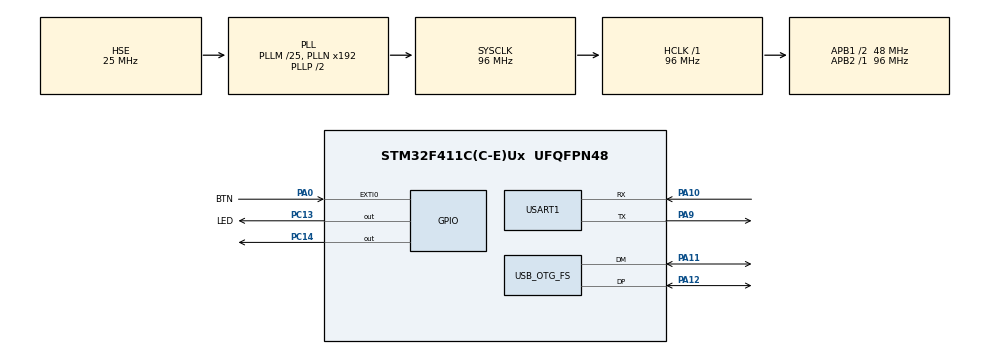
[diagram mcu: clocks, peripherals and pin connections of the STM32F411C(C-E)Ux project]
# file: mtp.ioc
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FREERTOS.Tasks01=mainTask,0,128,startMainTask,Default,NULL,Dynamic,NULL,NULL
FREERTOS.configUSE_NEWLIB_REENTRANT=1
Mcu.Family=STM32F4
Mcu.Name=STM32F411C(C-E)Ux
Mcu.Package=UFQFPN48
NVIC.OTG_FS_IRQn=true\:5\:0\:false\:false\:true\:true\:true\:true
NVIC.PriorityGroup=NVIC_PRIORITYGROUP_4
NVIC.TIM1_TRG_COM_TIM11_IRQn=true\:15\:0\:false\:false\:true\:false\:false\:true
NVIC.TimeBase=TIM1_TRG_COM_TIM11_IRQn
NVIC.TimeBaseIP=TIM11
PA0-WKUP.GPIO_Label=BTN
PA0-WKUP.GPIO_ModeDefaultEXTI=GPIO_MODE_IT_FALLING
PA0-WKUP.GPIO_PuPd=GPIO_PULLUP
PA0-WKUP.Signal=GPXTI0
PA10.Mode=Asynchronous
PA10.Signal=USART1_RX
PA11.Mode=Host_Only
PA11.Signal=USB_OTG_FS_DM
PA12.Mode=Host_Only
PA12.Signal=USB_OTG_FS_DP
PA13.Mode=Serial_Wire
PA13.Signal=SYS_JTMS-SWDIO
PA14.Mode=Serial_Wire
PA14.Signal=SYS_JTCK-SWCLK
PA9.Mode=Asynchronous
PA9.Signal=USART1_TX
PC13-ANTI_TAMP.GPIO_Label=LED
PC13-ANTI_TAMP.GPIO_ModeDefaultOutputPP=GPIO_MODE_OUTPUT_OD
PC13-ANTI_TAMP.PinState=GPIO_PIN_SET
PC13-ANTI_TAMP.Signal=GPIO_Output
PC14-OSC32_IN.Signal=GPIO_Output
PH0\ -\ OSC_IN.Mode=HSE-External-Oscillator
PH0\ -\ OSC_IN.Signal=RCC_OSC_IN
PH1\ -\ OSC_OUT.Mode=HSE-External-Oscillator
PH1\ -\ OSC_OUT.Signal=RCC_OSC_OUT
ProjectManager.HeapSize=0x200
ProjectManager.StackSize=0x400
ProjectManager.TargetToolchain=STM32CubeIDE
RCC.48MHZClocksFreq_Value=48000000
RCC.AHBFreq_Value=96000000
RCC.APB1CLKDivider=RCC_HCLK_DIV2
RCC.APB1Freq_Value=48000000
RCC.APB1TimFreq_Value=96000000
RCC.APB2Freq_Value=96000000
RCC.APB2TimFreq_Value=96000000
RCC.CortexFreq_Value=96000000
RCC.HCLKFreq_Value=96000000
RCC.HSE_VALUE=25000000
RCC.HSI_VALUE=16000000
RCC.LSE_VALUE=32768
RCC.PLLM=25
RCC.SYSCLKFreq_VALUE=96000000
RCC.SYSCLKSource=RCC_SYSCLKSOURCE_PLLCLK
RCC.VCOOutputFreq_Value=192000000
USART1.VirtualMode=VM_ASYNC
USB_HOST.BSP.number=1
USB_HOST.USBH_USE_OS-MTP_FS=0
USB_HOST.VirtualModeFS=Mtp
USB_HOST0.BSP.STBoard=false
USB_HOST0.BSP.api=Unknown
USB_HOST0.BSP.i2caddr=0
USB_HOST0.BSP.instance=PC14-OSC32_IN
USB_HOST0.BSP.ip=GPIO
USB_HOST0.BSP.mode=Output
USB_HOST0.BSP.name=Drive_VBUS_FS
USB_HOST0.BSP.solution=PC14-OSC32_IN
USB_OTG_FS.VirtualMode=Host_Only
USB_OTG_FS.phy_itface=HCD_PHY_EMBEDDED
VP_FREERTOS_VS_CMSIS_V1.Mode=CMSIS_V1
VP_SYS_VS_tim11.Mode=TIM11
VP_USB_HOST_VS_USB_HOST_MTP_FS.Mode=MTP_FS
board=custom

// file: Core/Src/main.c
/* USER CODE BEGIN Header */
/**
  ******************************************************************************
  * @file           : main.c
  * @brief          : Main program body
  ******************************************************************************
  * @attention
  *
  * <h2><center>&copy; Copyright (c) 2021 STMicroelectronics.
  * All rights reserved.</center></h2>
  *
  * This software component is licensed by ST under BSD 3-Clause license,
  * the "License"; You may not use this file except in compliance with the
  * License. You may obtain a copy of the License at:
  *                        opensource.org/licenses/BSD-3-Clause
  *
  ******************************************************************************
  */
/* USER CODE END Header */
#include "main.h"
#include "cmsis_os.h"
#include "usb_host.h"
#include "usb_host.h"

UART_HandleTypeDef huart1;

osThreadId mainTaskHandle;

void SystemClock_Config(void);
static void MX_GPIO_Init(void);
static void MX_USART1_UART_Init(void);
void startMainTask(void const * argument);

int main(void)
{
  /* USER CODE BEGIN 1 */

  char* foobar = "Testing 1 2 3";

  /* USER CODE END 1 */

  /* MCU Configuration--------------------------------------------------------*/

  /* Reset of all peripherals, Initializes the Flash interface and the Systick. */
  HAL_Init();

  /* Configure the system clock */
  SystemClock_Config();

  /* Initialize all configured peripherals */
  MX_GPIO_Init();
  MX_USART1_UART_Init();

  /* Create the thread(s) */
  /* definition and creation of mainTask */
  osThreadDef(mainTask, startMainTask, osPriorityNormal, 0, 128);
  mainTaskHandle = osThreadCreate(osThread(mainTask), NULL);

  /* Start scheduler */
  osKernelStart();

  /* We should never get here as control is now taken by the scheduler */
  /* Infinite loop */
  while (1)
  {

  }
}

void SystemClock_Config(void)
{
  RCC_OscInitTypeDef RCC_OscInitStruct = {0};
  RCC_ClkInitTypeDef RCC_ClkInitStruct = {0};

  /** Configure the main internal regulator output voltage
  */
  __HAL_RCC_PWR_CLK_ENABLE();
  __HAL_PWR_VOLTAGESCALING_CONFIG(PWR_REGULATOR_VOLTAGE_SCALE1);
  /** Initializes the RCC Oscillators according to the specified parameters
  * in the RCC_OscInitTypeDef structure.
  */
  RCC_OscInitStruct.OscillatorType = RCC_OSCILLATORTYPE_HSE;
  RCC_OscInitStruct.HSEState = RCC_HSE_ON;
  RCC_OscInitStruct.PLL.PLLState = RCC_PLL_ON;
  RCC_OscInitStruct.PLL.PLLSource = RCC_PLLSOURCE_HSE;
  RCC_OscInitStruct.PLL.PLLM = 25;
  RCC_OscInitStruct.PLL.PLLN = 192;
  RCC_OscInitStruct.PLL.PLLP = RCC_PLLP_DIV2;
  RCC_OscInitStruct.PLL.PLLQ = 4;
  if (HAL_RCC_OscConfig(&RCC_OscInitStruct) != HAL_OK)
  {
    Error_Handler();
  }
  /** Initializes the CPU, AHB and APB buses clocks
  */
  RCC_ClkInitStruct.ClockType = RCC_CLOCKTYPE_HCLK|RCC_CLOCKTYPE_SYSCLK
                              |RCC_CLOCKTYPE_PCLK1|RCC_CLOCKTYPE_PCLK2;
  RCC_ClkInitStruct.SYSCLKSource = RCC_SYSCLKSOURCE_PLLCLK;
  RCC_ClkInitStruct.AHBCLKDivider = RCC_SYSCLK_DIV1;
  RCC_ClkInitStruct.APB1CLKDivider = RCC_HCLK_DIV2;
  RCC_ClkInitStruct.APB2CLKDivider = RCC_HCLK_DIV1;

  if (HAL_RCC_ClockConfig(&RCC_ClkInitStruct, FLASH_LATENCY_3) != HAL_OK)
  {
    Error_Handler();
  }
}

static void MX_USART1_UART_Init(void)
{

  huart1.Instance = USART1;
  huart1.Init.BaudRate = 115200;
  huart1.Init.WordLength = UART_WORDLENGTH_8B;
  huart1.Init.StopBits = UART_STOPBITS_1;
  huart1.Init.Parity = UART_PARITY_NONE;
  huart1.Init.Mode = UART_MODE_TX_RX;
  huart1.Init.HwFlowCtl = UART_HWCONTROL_NONE;
  huart1.Init.OverSampling = UART_OVERSAMPLING_16;
  if (HAL_UART_Init(&huart1) != HAL_OK)
  {
    Error_Handler();
  }

}

static void MX_GPIO_Init(void)
{
  GPIO_InitTypeDef GPIO_InitStruct = {0};

  /* GPIO Ports Clock Enable */
  __HAL_RCC_GPIOC_CLK_ENABLE();
  __HAL_RCC_GPIOH_CLK_ENABLE();
  __HAL_RCC_GPIOA_CLK_ENABLE();

  /*Configure GPIO pin Output Level */
  HAL_GPIO_WritePin(LED_GPIO_Port, LED_Pin, GPIO_PIN_SET);

  /*Configure GPIO pin Output Level */
  HAL_GPIO_WritePin(GPIOC, GPIO_PIN_14, GPIO_PIN_RESET);

  /*Configure GPIO pin : LED_Pin */
  GPIO_InitStruct.Pin = LED_Pin;
  GPIO_InitStruct.Mode = GPIO_MODE_OUTPUT_OD;
  GPIO_InitStruct.Pull = GPIO_NOPULL;
  GPIO_InitStruct.Speed = GPIO_SPEED_FREQ_LOW;
  HAL_GPIO_Init(LED_GPIO_Port, &GPIO_InitStruct);

  /*Configure GPIO pin : PC14 */
  GPIO_InitStruct.Pin = GPIO_PIN_14;
  GPIO_InitStruct.Mode = GPIO_MODE_OUTPUT_PP;
  GPIO_InitStruct.Pull = GPIO_NOPULL;
  GPIO_InitStruct.Speed = GPIO_SPEED_FREQ_LOW;
  HAL_GPIO_Init(GPIOC, &GPIO_InitStruct);

  /*Configure GPIO pin : BTN_Pin */
  GPIO_InitStruct.Pin = BTN_Pin;
  GPIO_InitStruct.Mode = GPIO_MODE_IT_FALLING;
  GPIO_InitStruct.Pull = GPIO_PULLUP;
  HAL_GPIO_Init(BTN_GPIO_Port, &GPIO_InitStruct);

}

void startMainTask(void const * argument)
{
  /* init code for USB_HOST */
  MX_USB_HOST_Init();
  for(;;)
  {
    osDelay(1);
  }
}

void HAL_TIM_PeriodElapsedCallback(TIM_HandleTypeDef *htim)
{
  if (htim->Instance == TIM11) {
    HAL_IncTick();
  }
}

void Error_Handler(void)
{
  __disable_irq();
  while (1)
  {
  }
}

/************************ (C) COPYRIGHT STMicroelectronics *****END OF FILE****/
